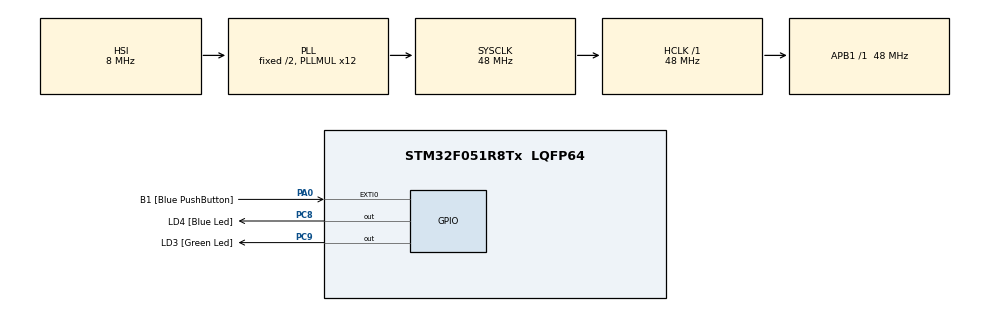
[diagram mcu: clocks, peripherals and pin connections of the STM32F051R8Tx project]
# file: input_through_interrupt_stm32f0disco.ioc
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Mcu.Family=STM32F0
Mcu.Name=STM32F051R8Tx
Mcu.Package=LQFP64
NVIC.EXTI0_1_IRQn=true\:0\:0\:false\:false\:true\:true\:true
PA0.GPIO_Label=B1 [Blue PushButton]
PA0.GPIO_ModeDefaultEXTI=GPIO_MODE_IT_RISING_FALLING
PA0.Signal=GPXTI0
PA13.GPIO_Label=SWDIO
PA13.Mode=Serial_Wire
PA13.Signal=SYS_SWDIO
PA14.GPIO_Label=SWCLK
PA14.Mode=Serial_Wire
PA14.Signal=SYS_SWCLK
PC8.GPIO_Label=LD4 [Blue Led]
PC8.Signal=GPIO_Output
PC9.GPIO_Label=LD3 [Green Led]
PC9.Signal=GPIO_Output
ProjectManager.HeapSize=0x200
ProjectManager.StackSize=0x400
ProjectManager.TargetToolchain=STM32CubeIDE
RCC.AHBFreq_Value=48000000
RCC.APB1Freq_Value=48000000
RCC.APB1TimFreq_Value=48000000
RCC.HCLKFreq_Value=48000000
RCC.PLLMUL=RCC_PLL_MUL12
RCC.SYSCLKFreq_VALUE=48000000
RCC.SYSCLKSource=RCC_SYSCLKSOURCE_PLLCLK
board=STM32F0DISCOVERY

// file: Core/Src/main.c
/* USER CODE BEGIN Header */
/**
  ******************************************************************************
  * @file           : main.c
  * @brief          : Main program body
  ******************************************************************************
  * @attention
  *
  * Copyright (c) 2021 STMicroelectronics.
  * All rights reserved.
  *
  * This software is licensed under terms that can be found in the LICENSE file
  * in the root directory of this software component.
  * If no LICENSE file comes with this software, it is provided AS-IS.
  *
  ******************************************************************************
  */
/* USER CODE END Header */
#include "main.h"

/* USER CODE BEGIN Includes */
#include "stm32f051_discovery.h"
#include "systick_timer.h"
#include "button_interrupt.h"
/* USER CODE END Includes */

/* USER CODE BEGIN PV */
SYSTick_Timer_t  timer_1, timer_2, timer_3;
/* USER CODE END PV */

void SystemClock_Config(void);
static void MX_GPIO_Init(void);

int main(void)
{

  /* MCU Configuration--------------------------------------------------------*/

  /* Reset of all peripherals, Initializes the Flash interface and the Systick. */
  HAL_Init();

  /* Configure the system clock */
  SystemClock_Config();

  /* Initialize all configured peripherals */
  MX_GPIO_Init();
  /* USER CODE BEGIN 2 */
  BSP_LED_Init(LED3);
  BSP_LED_Init(LED4);
  //BSP_PB_Init(BUTTON_USER, BUTTON_MODE_GPIO);
  user_button_state = BSP_PB_GetState(BUTTON_USER);
  start_systick_timer(&timer_1, 100);
  start_systick_timer(&timer_2, 100);
  start_systick_timer(&timer_3, 100);
  /* USER CODE END 2 */

  /* Infinite loop */
  while (1)
  {

    /* USER CODE BEGIN 3 */
    if(Timer_Expired == get_systick_timer(&timer_1))
    {
      BSP_LED_Toggle(LED4);
      start_systick_timer(&timer_1, 500);
    }
    if(user_button_state)
    { // BUTTON_USER pressed
      if(Timer_Expired == get_systick_timer(&timer_2))
      {
        BSP_LED_Toggle(LED3);
        start_systick_timer(&timer_2, 100);
      }
      start_systick_timer(&timer_3, 700);
    }
    else
    {
      if(Timer_Expired == get_systick_timer(&timer_3))
      {
        BSP_LED_Toggle(LED3);
        start_systick_timer(&timer_3, 700);
      }
      start_systick_timer(&timer_2, 100);
    }
  }
  /* USER CODE END 3 */
}

void SystemClock_Config(void)
{
  RCC_OscInitTypeDef RCC_OscInitStruct = {0};
  RCC_ClkInitTypeDef RCC_ClkInitStruct = {0};

  /** Initializes the RCC Oscillators according to the specified parameters
  * in the RCC_OscInitTypeDef structure.
  */
  RCC_OscInitStruct.OscillatorType = RCC_OSCILLATORTYPE_HSI;
  RCC_OscInitStruct.HSIState = RCC_HSI_ON;
  RCC_OscInitStruct.HSICalibrationValue = RCC_HSICALIBRATION_DEFAULT;
  RCC_OscInitStruct.PLL.PLLState = RCC_PLL_ON;
  RCC_OscInitStruct.PLL.PLLSource = RCC_PLLSOURCE_HSI;
  RCC_OscInitStruct.PLL.PLLMUL = RCC_PLL_MUL12;
  RCC_OscInitStruct.PLL.PREDIV = RCC_PREDIV_DIV1;
  if (HAL_RCC_OscConfig(&RCC_OscInitStruct) != HAL_OK)
  {
    Error_Handler();
  }
  /** Initializes the CPU, AHB and APB buses clocks
  */
  RCC_ClkInitStruct.ClockType = RCC_CLOCKTYPE_HCLK|RCC_CLOCKTYPE_SYSCLK
                              |RCC_CLOCKTYPE_PCLK1;
  RCC_ClkInitStruct.SYSCLKSource = RCC_SYSCLKSOURCE_PLLCLK;
  RCC_ClkInitStruct.AHBCLKDivider = RCC_SYSCLK_DIV1;
  RCC_ClkInitStruct.APB1CLKDivider = RCC_HCLK_DIV1;

  if (HAL_RCC_ClockConfig(&RCC_ClkInitStruct, FLASH_LATENCY_1) != HAL_OK)
  {
    Error_Handler();
  }
}

static void MX_GPIO_Init(void)
{
  GPIO_InitTypeDef GPIO_InitStruct = {0};

  /* GPIO Ports Clock Enable */
  __HAL_RCC_GPIOA_CLK_ENABLE();
  __HAL_RCC_GPIOC_CLK_ENABLE();

  /*Configure GPIO pin Output Level */
  HAL_GPIO_WritePin(GPIOC, LD4_Pin|LD3_Pin, GPIO_PIN_RESET);

  /*Configure GPIO pin : B1_Pin */
  GPIO_InitStruct.Pin = B1_Pin;
  GPIO_InitStruct.Mode = GPIO_MODE_IT_RISING_FALLING;
  GPIO_InitStruct.Pull = GPIO_NOPULL;
  HAL_GPIO_Init(B1_GPIO_Port, &GPIO_InitStruct);

  /*Configure GPIO pins : LD4_Pin LD3_Pin */
  GPIO_InitStruct.Pin = LD4_Pin|LD3_Pin;
  GPIO_InitStruct.Mode = GPIO_MODE_OUTPUT_PP;
  GPIO_InitStruct.Pull = GPIO_NOPULL;
  GPIO_InitStruct.Speed = GPIO_SPEED_FREQ_LOW;
  HAL_GPIO_Init(GPIOC, &GPIO_InitStruct);

  /* EXTI interrupt init*/
  HAL_NVIC_SetPriority(EXTI0_1_IRQn, 0, 0);
  HAL_NVIC_EnableIRQ(EXTI0_1_IRQn);

}

void Error_Handler(void)
{
  __disable_irq();
  while (1)
  {
  }
}
